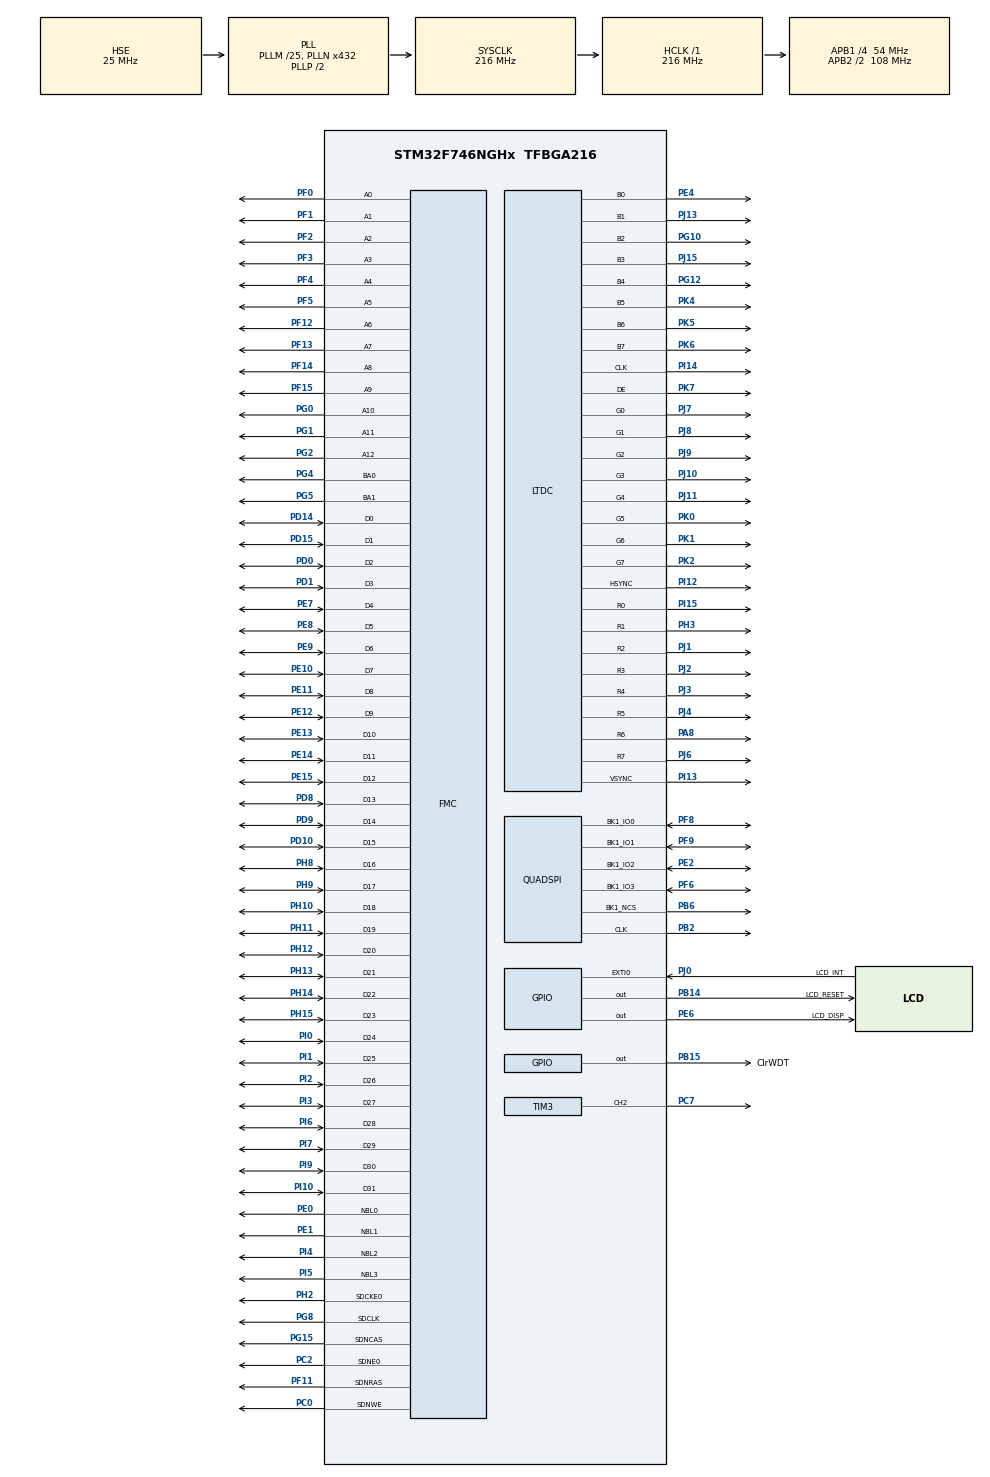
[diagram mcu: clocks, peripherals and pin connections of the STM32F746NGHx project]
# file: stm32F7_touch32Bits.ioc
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CORTEX_M7.CPU_DCache=Disabled
CORTEX_M7.CPU_ICache=Disabled
DMA2D.ColorMode=DMA2D_OUTPUT_ARGB8888
FMC.CASLatency1=FMC_SDRAM_CAS_LATENCY_3
FMC.ColumnBitsNumber1=FMC_SDRAM_COLUMN_BITS_NUM_9
FMC.ExitSelfRefreshDelay1=8
FMC.LoadToActiveDelay1=2
FMC.RCDDelay1=2
FMC.RPDelay1=2
FMC.ReadBurst1=FMC_SDRAM_RBURST_DISABLE
FMC.ReadPipeDelay1=FMC_SDRAM_RPIPE_DELAY_1
FMC.ReadPipeDelay2=FMC_SDRAM_RPIPE_DELAY_1
FMC.RowCycleDelay1=7
FMC.SDClockPeriod1=FMC_SDRAM_CLOCK_PERIOD_2
FMC.SDClockPeriod2=FMC_SDRAM_CLOCK_PERIOD_2
FMC.SelfRefreshTime1=5
FMC.WriteRecoveryTime1=3
FREERTOS.Tasks01=defaultTask,0,128,StartDefaultTask,Default,NULL,Dynamic,NULL,NULL;myTask02,-3,8192,StartTask02,Default,NULL,Dynamic,NULL,NULL;myTask03,-3,128,StartTask03,Default,NULL,Dynamic,NULL,NULL
FREERTOS.configENABLE_FPU=1
FREERTOS.configTOTAL_HEAP_SIZE=52768
FREERTOS.configUSE_NEWLIB_REENTRANT=1
LTDC.ActiveW=800
LTDC.Alpha0_L0=0
LTDC.Alpha_L0=255
LTDC.DEPolarity=LTDC_DEPOLARITY_AL
LTDC.FBStartAdress_L0=0xC0000000
LTDC.HBP=45
LTDC.HFP=210
LTDC.HSPolarity=LTDC_HSPOLARITY_AL
LTDC.HSync=2
LTDC.ImageHeight_L0=480
LTDC.ImageWidth_L0=800
LTDC.Layers=0
LTDC.PCPolarity=LTDC_PCPOLARITY_IPC
LTDC.PixelFormat_L0=LTDC_PIXEL_FORMAT_ARGB8888
LTDC.VBP=22
LTDC.VFP=22
LTDC.VSPolarity=LTDC_VSPOLARITY_AL
LTDC.VSync=2
LTDC.WindowX1_L0=800
LTDC.WindowY1_L0=480
Mcu.Family=STM32F7
Mcu.Name=STM32F746NGHx
Mcu.Package=TFBGA216
NVIC.DMA2D_IRQn=true\:5\:0\:false\:false\:true\:true\:true\:true\:true
NVIC.EXTI0_IRQn=true\:5\:0\:false\:false\:true\:true\:true\:true\:true
NVIC.LTDC_ER_IRQn=true\:5\:0\:false\:false\:true\:true\:true\:true\:true
NVIC.LTDC_IRQn=true\:5\:0\:false\:false\:true\:true\:true\:true\:true
NVIC.PriorityGroup=NVIC_PRIORITYGROUP_4
NVIC.TIM2_IRQn=true\:5\:0\:false\:false\:true\:true\:true\:true\:true
NVIC.TIM6_DAC_IRQn=true\:15\:0\:false\:false\:true\:false\:false\:true\:true
NVIC.TimeBase=TIM6_DAC_IRQn
NVIC.TimeBaseIP=TIM6
PA13.Mode=Serial_Wire
PA13.Signal=SYS_JTMS-SWDIO
PA14.Mode=Serial_Wire
PA14.Signal=SYS_JTCK-SWCLK
PA8.GPIO_Speed=GPIO_SPEED_FREQ_VERY_HIGH
PA8.Mode=RGB888
PA8.Signal=LTDC_R6
PB14.GPIO_Label=LCD_RESET
PB14.Signal=GPIO_Output
PB15.GPIO_Label=ClrWDT
PB15.Signal=GPIO_Output
PB2.Mode=Single Bank 1
PB2.Signal=QUADSPI_CLK
PB6.Mode=Single Bank 1
PB6.Signal=QUADSPI_BK1_NCS
PC0.Signal=FMC_SDNWE
PC14/OSC32_IN.Mode=LSE-External-Clock-Source
PC14/OSC32_IN.Signal=RCC_OSC32_IN
PC15/OSC32_OUT.Mode=LSE-External-Clock-Source
PC15/OSC32_OUT.Signal=RCC_OSC32_OUT
PC2.Mode=SdramChipSelect1_1
PC2.Signal=FMC_SDNE0
PC7.Signal=S_TIM3_CH2
PD0.Signal=FMC_D2_DA2
PD1.Signal=FMC_D3_DA3
PD10.Signal=FMC_D15_DA15
PD14.Signal=FMC_D0_DA0
PD15.Signal=FMC_D1_DA1
PD8.Signal=FMC_D13_DA13
PD9.Signal=FMC_D14_DA14
PE0.Signal=FMC_NBL0
PE1.Signal=FMC_NBL1
PE10.Signal=FMC_D7_DA7
PE11.Signal=FMC_D8_DA8
PE12.Signal=FMC_D9_DA9
PE13.Signal=FMC_D10_DA10
PE14.Signal=FMC_D11_DA11
PE15.Signal=FMC_D12_DA12
PE2.Mode=Single Bank 1
PE2.Signal=QUADSPI_BK1_IO2
PE4.GPIO_Speed=GPIO_SPEED_FREQ_VERY_HIGH
PE4.Mode=RGB888
PE4.Signal=LTDC_B0
PE6.GPIO_Label=LCD_DISP
PE6.Signal=GPIO_Output
PE7.Signal=FMC_D4_DA4
PE8.Signal=FMC_D5_DA5
PE9.Signal=FMC_D6_DA6
PF0.Signal=FMC_A0
PF1.Signal=FMC_A1
PF11.Signal=FMC_SDNRAS
PF12.Signal=FMC_A6
PF13.Signal=FMC_A7
PF14.Signal=FMC_A8
PF15.Signal=FMC_A9
PF2.Signal=FMC_A2
PF3.Signal=FMC_A3
PF4.Signal=FMC_A4
PF5.Signal=FMC_A5
PF6.Mode=Single Bank 1
PF6.Signal=QUADSPI_BK1_IO3
PF8.Mode=Single Bank 1
PF8.Signal=QUADSPI_BK1_IO0
PF9.Mode=Single Bank 1
PF9.Signal=QUADSPI_BK1_IO1
PG0.Signal=FMC_A10
PG1.Signal=FMC_A11
PG10.GPIO_Speed=GPIO_SPEED_FREQ_VERY_HIGH
PG10.Mode=RGB888
PG10.Signal=LTDC_B2
PG12.GPIO_Speed=GPIO_SPEED_FREQ_VERY_HIGH
PG12.Mode=RGB888
PG12.Signal=LTDC_B4
PG15.Signal=FMC_SDNCAS
PG2.Signal=FMC_A12
PG4.Signal=FMC_A14_BA0
PG5.Signal=FMC_A15_BA1
PG8.Signal=FMC_SDCLK
PH0/OSC_IN.Mode=HSE-External-Oscillator
PH0/OSC_IN.Signal=RCC_OSC_IN
PH1/OSC_OUT.Mode=HSE-External-Oscillator
PH1/OSC_OUT.Signal=RCC_OSC_OUT
PH10.Signal=FMC_D18
PH11.Signal=FMC_D19
PH12.Signal=FMC_D20
PH13.Signal=FMC_D21
PH14.Signal=FMC_D22
PH15.Signal=FMC_D23
PH2.Mode=SdramChipSelect1_1
PH2.Signal=FMC_SDCKE0
PH3.GPIO_Speed=GPIO_SPEED_FREQ_VERY_HIGH
PH3.Mode=RGB888
PH3.Signal=LTDC_R1
PH4.GPIO_Pu=GPIO_PULLUP
PH4.Signal=I2C2_SCL
PH5.GPIO_Pu=GPIO_PULLUP
PH5.Signal=I2C2_SDA
PH8.Signal=FMC_D16
PH9.Signal=FMC_D17
PI0.Signal=FMC_D24
PI1.Signal=FMC_D25
PI10.Signal=FMC_D31
PI12.GPIO_Speed=GPIO_SPEED_FREQ_VERY_HIGH
PI12.Mode=RGB888
PI12.Signal=LTDC_HSYNC
PI13.GPIO_Speed=GPIO_SPEED_FREQ_VERY_HIGH
PI13.Mode=RGB888
PI13.Signal=LTDC_VSYNC
PI14.GPIO_Speed=GPIO_SPEED_FREQ_VERY_HIGH
PI14.Mode=RGB888
PI14.Signal=LTDC_CLK
PI15.GPIO_Speed=GPIO_SPEED_FREQ_VERY_HIGH
PI15.Mode=RGB888
PI15.Signal=LTDC_R0
PI2.Signal=FMC_D26
PI3.Signal=FMC_D27
PI4.Signal=FMC_NBL2
PI5.Signal=FMC_NBL3
PI6.Signal=FMC_D28
PI7.Signal=FMC_D29
PI9.Signal=FMC_D30
PJ0.GPIO_Label=LCD_INT
PJ0.GPIO_ModeDefaultEXTI=GPIO_MODE_IT_FALLING
PJ0.Signal=GPXTI0
PJ1.GPIO_Speed=GPIO_SPEED_FREQ_VERY_HIGH
PJ1.Mode=RGB888
PJ1.Signal=LTDC_R2
PJ10.GPIO_Speed=GPIO_SPEED_FREQ_VERY_HIGH
PJ10.Mode=RGB888
PJ10.Signal=LTDC_G3
PJ11.GPIO_Speed=GPIO_SPEED_FREQ_VERY_HIGH
PJ11.Mode=RGB888
PJ11.Signal=LTDC_G4
PJ13.GPIO_Speed=GPIO_SPEED_FREQ_VERY_HIGH
PJ13.Mode=RGB888
PJ13.Signal=LTDC_B1
PJ15.GPIO_Speed=GPIO_SPEED_FREQ_VERY_HIGH
PJ15.Mode=RGB888
PJ15.Signal=LTDC_B3
PJ2.GPIO_Speed=GPIO_SPEED_FREQ_VERY_HIGH
PJ2.Mode=RGB888
PJ2.Signal=LTDC_R3
PJ3.GPIO_Speed=GPIO_SPEED_FREQ_VERY_HIGH
PJ3.Mode=RGB888
PJ3.Signal=LTDC_R4
PJ4.GPIO_Speed=GPIO_SPEED_FREQ_VERY_HIGH
PJ4.Mode=RGB888
PJ4.Signal=LTDC_R5
PJ6.GPIO_Speed=GPIO_SPEED_FREQ_VERY_HIGH
PJ6.Mode=RGB888
PJ6.Signal=LTDC_R7
PJ7.GPIO_Speed=GPIO_SPEED_FREQ_VERY_HIGH
PJ7.Mode=RGB888
PJ7.Signal=LTDC_G0
PJ8.GPIO_Speed=GPIO_SPEED_FREQ_VERY_HIGH
PJ8.Mode=RGB888
PJ8.Signal=LTDC_G1
PJ9.GPIO_Speed=GPIO_SPEED_FREQ_VERY_HIGH
PJ9.Mode=RGB888
PJ9.Signal=LTDC_G2
PK0.GPIO_Speed=GPIO_SPEED_FREQ_VERY_HIGH
PK0.Mode=RGB888
PK0.Signal=LTDC_G5
PK1.GPIO_Speed=GPIO_SPEED_FREQ_VERY_HIGH
PK1.Mode=RGB888
PK1.Signal=LTDC_G6
PK2.GPIO_Speed=GPIO_SPEED_FREQ_VERY_HIGH
PK2.Mode=RGB888
PK2.Signal=LTDC_G7
PK4.GPIO_Speed=GPIO_SPEED_FREQ_VERY_HIGH
PK4.Mode=RGB888
PK4.Signal=LTDC_B5
PK5.GPIO_Speed=GPIO_SPEED_FREQ_VERY_HIGH
PK5.Mode=RGB888
PK5.Signal=LTDC_B6
PK6.GPIO_Speed=GPIO_SPEED_FREQ_VERY_HIGH
PK6.Mode=RGB888
PK6.Signal=LTDC_B7
PK7.GPIO_Speed=GPIO_SPEED_FREQ_VERY_HIGH
PK7.Mode=RGB888
PK7.Signal=LTDC_DE
ProjectManager.HeapSize=0x200
ProjectManager.StackSize=0x400
ProjectManager.TargetToolchain=STM32CubeIDE
QUADSPI.ChipSelectHighTime=QSPI_CS_HIGH_TIME_2_CYCLE
QUADSPI.ClockPrescaler=2
QUADSPI.FifoThreshold=4
QUADSPI.FlashSize=31
QUADSPI.SampleShifting=QSPI_SAMPLE_SHIFTING_HALFCYCLE
RCC.AHBFreq_Value=216000000
RCC.APB1CLKDivider=RCC_HCLK_DIV4
RCC.APB1Freq_Value=54000000
RCC.APB1TimFreq_Value=108000000
RCC.APB2CLKDivider=RCC_HCLK_DIV2
RCC.APB2Freq_Value=108000000
RCC.APB2TimFreq_Value=216000000
RCC.CortexFreq_Value=216000000
RCC.HCLKFreq_Value=216000000
RCC.HSE_VALUE=25000000
RCC.HSI_VALUE=16000000
RCC.LSE_VALUE=32768
RCC.PLLM=25
RCC.PLLN=432
RCC.PLLSAIR=3
RCC.PLLSourceVirtual=RCC_PLLSOURCE_HSE
RCC.SYSCLKFreq_VALUE=216000000
RCC.SYSCLKSource=RCC_SYSCLKSOURCE_PLLCLK
RCC.USBFreq_Value=216000000
RCC.VCOOutputFreq_Value=432000000
SH.FMC_A0.0=FMC_A0,13b-sda1
SH.FMC_A1.0=FMC_A1,13b-sda1
SH.FMC_A10.0=FMC_A10,13b-sda1
SH.FMC_A11.0=FMC_A11,13b-sda1
SH.FMC_A12.0=FMC_A12,13b-sda1
SH.FMC_A14_BA0.0=FMC_BA0,FourSdramBanks1
SH.FMC_A15_BA1.0=FMC_BA1,FourSdramBanks1
SH.FMC_A2.0=FMC_A2,13b-sda1
SH.FMC_A3.0=FMC_A3,13b-sda1
SH.FMC_A4.0=FMC_A4,13b-sda1
SH.FMC_A5.0=FMC_A5,13b-sda1
SH.FMC_A6.0=FMC_A6,13b-sda1
SH.FMC_A7.0=FMC_A7,13b-sda1
SH.FMC_A8.0=FMC_A8,13b-sda1
SH.FMC_A9.0=FMC_A9,13b-sda1
SH.FMC_D0_DA0.0=FMC_D0,sd-32b-d1
SH.FMC_D10_DA10.0=FMC_D10,sd-32b-d1
SH.FMC_D11_DA11.0=FMC_D11,sd-32b-d1
SH.FMC_D12_DA12.0=FMC_D12,sd-32b-d1
SH.FMC_D13_DA13.0=FMC_D13,sd-32b-d1
SH.FMC_D14_DA14.0=FMC_D14,sd-32b-d1
SH.FMC_D15_DA15.0=FMC_D15,sd-32b-d1
SH.FMC_D16.0=FMC_D16,sd-32b-d1
SH.FMC_D17.0=FMC_D17,sd-32b-d1
SH.FMC_D18.0=FMC_D18,sd-32b-d1
SH.FMC_D19.0=FMC_D19,sd-32b-d1
SH.FMC_D1_DA1.0=FMC_D1,sd-32b-d1
SH.FMC_D20.0=FMC_D20,sd-32b-d1
SH.FMC_D21.0=FMC_D21,sd-32b-d1
SH.FMC_D22.0=FMC_D22,sd-32b-d1
SH.FMC_D23.0=FMC_D23,sd-32b-d1
SH.FMC_D24.0=FMC_D24,sd-32b-d1
SH.FMC_D25.0=FMC_D25,sd-32b-d1
SH.FMC_D26.0=FMC_D26,sd-32b-d1
SH.FMC_D27.0=FMC_D27,sd-32b-d1
SH.FMC_D28.0=FMC_D28,sd-32b-d1
SH.FMC_D29.0=FMC_D29,sd-32b-d1
SH.FMC_D2_DA2.0=FMC_D2,sd-32b-d1
SH.FMC_D30.0=FMC_D30,sd-32b-d1
SH.FMC_D31.0=FMC_D31,sd-32b-d1
SH.FMC_D3_DA3.0=FMC_D3,sd-32b-d1
SH.FMC_D4_DA4.0=FMC_D4,sd-32b-d1
SH.FMC_D5_DA5.0=FMC_D5,sd-32b-d1
SH.FMC_D6_DA6.0=FMC_D6,sd-32b-d1
SH.FMC_D7_DA7.0=FMC_D7,sd-32b-d1
SH.FMC_D8_DA8.0=FMC_D8,sd-32b-d1
SH.FMC_D9_DA9.0=FMC_D9,sd-32b-d1
SH.FMC_NBL0.0=FMC_NBL0,Sd4ByteEnable1
SH.FMC_NBL1.0=FMC_NBL1,Sd4ByteEnable1
SH.FMC_NBL2.0=FMC_NBL2,Sd4ByteEnable1
SH.FMC_NBL3.0=FMC_NBL3,Sd4ByteEnable1
SH.FMC_SDCLK.0=FMC_SDCLK,13b-sda1
SH.FMC_SDNCAS.0=FMC_SDNCAS,13b-sda1
SH.FMC_SDNRAS.0=FMC_SDNRAS,13b-sda1
SH.FMC_SDNWE.0=FMC_SDNWE,13b-sda1
SH.S_TIM3_CH2.0=TIM3_CH2,PWM Generation2 CH2
STMicroelectronics.X-CUBE-TOUCHGFX.4.24.1.ApplicationCcGraphicsJjApplication=TouchGFXOoGenerator
STMicroelectronics.X-CUBE-TOUCHGFX.4.24.1.tgfx_address1=0xC0000000
STMicroelectronics.X-CUBE-TOUCHGFX.4.24.1.tgfx_display_interface=disp_ltdc
STMicroelectronics.X-CUBE-TOUCHGFX.4.24.1.tgfx_hardware_accelerator=dma_2d
STMicroelectronics.X-CUBE-TOUCHGFX.4.24.1.tgfx_location=By Address
STMicroelectronics.X-CUBE-TOUCHGFX.4.24.1.tgfx_vsync=vsync_ltdc
STMicroelectronics.X-CUBE-TOUCHGFX.4.24.1_IsPackSelfContextualization=true
TIM2.Period=100
TIM2.Prescaler=54
TIM3.Channel-PWM\ Generation2\ CH2=TIM_CHANNEL_2
TIM3.Period=100
TIM3.Prescaler=108
TIM3.Pulse-PWM\ Generation2\ CH2=50
VP_CRC_VS_CRC.Mode=CRC_Activate
VP_DMA2D_VS_DMA2D.Mode=DMA2D_Activate
VP_FREERTOS_VS_CMSIS_V1.Mode=CMSIS_V1
VP_STMicroelectronics.X-CUBE-TOUCHGFX_VS_GraphicsJjApplication_4.24.1.Mode=GraphicsJjApplication
VP_SYS_VS_tim6.Mode=TIM6
VP_TIM2_VS_ClockSourceINT.Mode=Internal
VP_TIM3_VS_ClockSourceINT.Mode=Internal
board=custom

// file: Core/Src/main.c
/* USER CODE BEGIN Header */
/**
  ******************************************************************************
  * @file           : main.c
  * @brief          : Main program body
  ******************************************************************************
  * @attention
  *
  * Copyright (c) 2025 STMicroelectronics.
  * All rights reserved.
  *
  * This software is licensed under terms that can be found in the LICENSE file
  * in the root directory of this software component.
  * If no LICENSE file comes with this software, it is provided AS-IS.
  *
  ******************************************************************************
  */
/* USER CODE END Header */
#include "main.h"
#include "cmsis_os.h"
#include "app_touchgfx.h"

/* USER CODE BEGIN Includes */
#include "GT911.h"
/* USER CODE END Includes */

/* USER CODE BEGIN PD */
#define SDRAM_START_ADDR ((uint32_t)0xC0000000)
#define SDRAM_SIZE       ((uint32_t)0x200000) // 2MB for testing
#define SDRAM_TEST_DATA  ((uint32_t)0x12345678)

#define SDRAM_START_ADDRESS 0xC0000000

#define SDRAM_TIMEOUT     ((uint32_t)0xFFFF)

#define SDRAM_MODEREG_BURST_LENGTH_1             ((uint16_t)0x0000)
#define SDRAM_MODEREG_BURST_LENGTH_2             ((uint16_t)0x0001)
#define SDRAM_MODEREG_BURST_LENGTH_4             ((uint16_t)0x0002)
#define SDRAM_MODEREG_BURST_LENGTH_8             ((uint16_t)0x0004)
#define SDRAM_MODEREG_BURST_TYPE_SEQUENTIAL      ((uint16_t)0x0000)
#define SDRAM_MODEREG_BURST_TYPE_INTERLEAVED     ((uint16_t)0x0008)
#define SDRAM_MODEREG_CAS_LATENCY_2              ((uint16_t)0x0020)
#define SDRAM_MODEREG_CAS_LATENCY_3              ((uint16_t)0x0030)
#define SDRAM_MODEREG_OPERATING_MODE_STANDARD    ((uint16_t)0x0000)
#define SDRAM_MODEREG_WRITEBURST_MODE_PROGRAMMED ((uint16_t)0x0000)
#define SDRAM_MODEREG_WRITEBURST_MODE_SINGLE     ((uint16_t)0x0200)
/* USER CODE END PD */

CRC_HandleTypeDef hcrc;

DMA2D_HandleTypeDef hdma2d;

LTDC_HandleTypeDef hltdc;

QSPI_HandleTypeDef hqspi;

TIM_HandleTypeDef htim2;
TIM_HandleTypeDef htim3;

SDRAM_HandleTypeDef hsdram1;

osThreadId defaultTaskHandle;
osThreadId myTask02Handle;
osThreadId myTask03Handle;

void SystemClock_Config(void);
static void MX_GPIO_Init(void);
static void MX_FMC_Init(void);
static void MX_LTDC_Init(void);
static void MX_DMA2D_Init(void);
static void MX_TIM3_Init(void);
static void MX_CRC_Init(void);
static void MX_QUADSPI_Init(void);
static void MX_TIM2_Init(void);
void StartDefaultTask(void const * argument);
void StartTask02(void const * argument);
void StartTask03(void const * argument);

/* USER CODE BEGIN 0 */
//void MX_QUADSPI_Init(void)
//{
//    /* QSPI init function */
//    hqspi.Instance = QUADSPI;
//    hqspi.Init.ClockPrescaler = 2; // 216MHz / (2+1) = 72MHz QSPI Clock
//    hqspi.Init.FifoThreshold = 4;
//    hqspi.Init.SampleShifting = QSPI_SAMPLE_SHIFTING_HALFCYCLE;
//    hqspi.Init.FlashSize = 31; // 2^31 = 2GB address space (we need for 256Mbit = 32MB)
//    hqspi.Init.ChipSelectHighTime = QSPI_CS_HIGH_TIME_2_CYCLE;
//    hqspi.Init.ClockMode = QSPI_CLOCK_MODE_0;
//    hqspi.Init.FlashID = QSPI_FLASH_ID_1; // Bank 1
//    hqspi.Init.DualFlash = QSPI_DUALFLASH_DISABLE;
//
//    if (HAL_QSPI_Init(&hqspi) != HAL_OK)
//    {
//        Error_Handler();
//    }
//
//    /* Enter 4-byte addressing mode for W25Q256 */
//    QSPI_CommandTypeDef sCommand = {0};
//
//    sCommand.InstructionMode = QSPI_INSTRUCTION_1_LINE;
//    sCommand.Instruction = 0xB7; // Enter 4-byte address mode
//    sCommand.AddressMode = QSPI_ADDRESS_NONE;
//    sCommand.AlternateByteMode = QSPI_ALTERNATE_BYTES_NONE;
//    sCommand.DataMode = QSPI_DATA_NONE;
//    sCommand.DummyCycles = 0;
//
//    if (HAL_QSPI_Command(&hqspi, &sCommand, HAL_QPSI_TIMEOUT_DEFAULT_VALUE) != HAL_OK)
//    {
//        Error_Handler();
//    }
//}

void QSPI_EnableMemoryMappedMode(void)
{
    QSPI_CommandTypeDef sCommand = {0};
    QSPI_MemoryMappedTypeDef sMemMappedCfg = {0};

    /* Configure QSPI command for read */
    sCommand.InstructionMode = QSPI_INSTRUCTION_1_LINE;
    sCommand.Instruction = 0xEB; // Quad I/O Fast Read
    sCommand.AddressMode = QSPI_ADDRESS_4_LINES;
    sCommand.AddressSize = QSPI_ADDRESS_32_BITS;
    sCommand.AlternateByteMode = QSPI_ALTERNATE_BYTES_4_LINES;
    sCommand.AlternateBytesSize = QSPI_ALTERNATE_BYTES_8_BITS;
    sCommand.AlternateBytes = 0x00; // Typically 0x00 for Winbond
    sCommand.DataMode = QSPI_DATA_4_LINES;
    sCommand.DummyCycles = 6; // 6 dummy cycles is typical (datasheet recommends 6 for 72MHz)
    sCommand.DdrMode = QSPI_DDR_MODE_DISABLE;
    sCommand.DdrHoldHalfCycle = QSPI_DDR_HHC_ANALOG_DELAY;
    sCommand.SIOOMode = QSPI_SIOO_INST_EVERY_CMD;

    /* Configure memory mapped mode */
    sMemMappedCfg.TimeOutActivation = QSPI_TIMEOUT_COUNTER_DISABLE;
    sMemMappedCfg.TimeOutPeriod = 0;

    if (HAL_QSPI_MemoryMapped(&hqspi, &sCommand, &sMemMappedCfg) != HAL_OK)
    {
        Error_Handler();
    }
}

/**
  * @brief  Perform the SDRAM external memory initialization sequence
  * @param  hsdram: SDRAM handle
  * @param  Command: Pointer to SDRAM command structure
  * @retval None
  */
static void BSP_SDRAM_Initialization_Sequence(SDRAM_HandleTypeDef *hsdram, FMC_SDRAM_CommandTypeDef *Command)
{
  __IO uint32_t tmpmrd =0;
  /* Step 3:  Configure a clock configuration enable command */
  Command->CommandMode = FMC_SDRAM_CMD_CLK_ENABLE;
  Command->CommandTarget = FMC_SDRAM_CMD_TARGET_BANK1;
  Command->AutoRefreshNumber = 1;
  Command->ModeRegisterDefinition = 0;

  /* Send the command */
  HAL_SDRAM_SendCommand(hsdram, Command, SDRAM_TIMEOUT);

  /* Step 4: Insert 100 us minimum delay */
  /* Inserted delay is equal to 1 ms due to systick time base unit (ms) */
  HAL_Delay(1);

  /* Step 5: Configure a PALL (precharge all) command */
  Command->CommandMode = FMC_SDRAM_CMD_PALL;
  Command->CommandTarget = FMC_SDRAM_CMD_TARGET_BANK1;
  Command->AutoRefreshNumber = 1;
  Command->ModeRegisterDefinition = 0;

  /* Send the command */
  HAL_SDRAM_SendCommand(hsdram, Command, SDRAM_TIMEOUT);

  /* Step 6 : Configure a Auto-Refresh command */
  Command->CommandMode = FMC_SDRAM_CMD_AUTOREFRESH_MODE;
  Command->CommandTarget = FMC_SDRAM_CMD_TARGET_BANK1;
  Command->AutoRefreshNumber = 8;
  Command->ModeRegisterDefinition = 0;

  /* Send the command */
  HAL_SDRAM_SendCommand(hsdram, Command, SDRAM_TIMEOUT);

  /* Step 7: Program the external memory mode register */
  tmpmrd = (uint32_t)SDRAM_MODEREG_BURST_LENGTH_1          |
                     SDRAM_MODEREG_BURST_TYPE_SEQUENTIAL   |
                     SDRAM_MODEREG_CAS_LATENCY_2           |
                     SDRAM_MODEREG_OPERATING_MODE_STANDARD |
                     SDRAM_MODEREG_WRITEBURST_MODE_SINGLE;

  Command->CommandMode = FMC_SDRAM_CMD_LOAD_MODE;
  Command->CommandTarget = FMC_SDRAM_CMD_TARGET_BANK1;
  Command->AutoRefreshNumber = 1;
  Command->ModeRegisterDefinition = tmpmrd;

  /* Send the command */
  HAL_SDRAM_SendCommand(hsdram, Command, SDRAM_TIMEOUT);

  /* Step 8: Set the refresh rate counter */
  /* (15.62 us x Freq) - 20 */
  /* Set the device refresh counter */
  hsdram->Instance->SDRTR |= ((uint32_t)((1292)<< 1));

}

uint8_t wdata[] = {0, 0, 0, 0, 0};
uint8_t rdata[10];

void MPU_Config(void)
{
    MPU_Region_InitTypeDef MPU_InitStruct = {0};

    HAL_MPU_Disable();

    // Configure MPU region for 32MB QSPI at 0x90000000
    MPU_InitStruct.Enable           = MPU_REGION_ENABLE;
    MPU_InitStruct.BaseAddress      = 0x90000000;
    MPU_InitStruct.Size             = MPU_REGION_SIZE_32MB;
    MPU_InitStruct.AccessPermission = MPU_REGION_FULL_ACCESS;
    MPU_InitStruct.IsBufferable     = MPU_ACCESS_NOT_BUFFERABLE;
    MPU_InitStruct.IsCacheable      = MPU_ACCESS_CACHEABLE;
    MPU_InitStruct.IsShareable      = MPU_ACCESS_NOT_SHAREABLE;
    MPU_InitStruct.Number           = MPU_REGION_NUMBER0;
    MPU_InitStruct.TypeExtField     = MPU_TEX_LEVEL1;
    MPU_InitStruct.SubRegionDisable = 0x00;
    MPU_InitStruct.DisableExec      = MPU_INSTRUCTION_ACCESS_DISABLE;

    HAL_MPU_ConfigRegion(&MPU_InitStruct);
    HAL_MPU_Enable(MPU_PRIVILEGED_DEFAULT);
}

/* USER CODE END 0 */

int main(void)
{

  /* USER CODE BEGIN 1 */
//	MPU_Config();
  /* USER CODE END 1 */

  /* MCU Configuration--------------------------------------------------------*/

  /* Reset of all peripherals, Initializes the Flash interface and the Systick. */
  HAL_Init();

  /* Configure the system clock */
  SystemClock_Config();

  /* Initialize all configured peripherals */
  MX_GPIO_Init();
  MX_FMC_Init();
  MX_LTDC_Init();
  MX_DMA2D_Init();
  MX_TIM3_Init();
  MX_CRC_Init();
  MX_QUADSPI_Init();
  MX_TIM2_Init();
  MX_TouchGFX_Init();
  /* Call PreOsInit function */
  MX_TouchGFX_PreOSInit();
  /* USER CODE BEGIN 2 */

  HAL_GPIO_WritePin(LCD_DISP_GPIO_Port, LCD_DISP_Pin, GPIO_PIN_SET);

  htim3.Instance->CCR2 = 1;
  HAL_TIM_PWM_Start(&htim3, TIM_CHANNEL_2);   // Start PWM on channel 2
  HAL_TIM_Base_Start_IT(&htim2);

  //memcpy(0, ram_buffer, image_size);
//  for(uint32_t i =0 ;i<2000;i+=5)
//  {
//	  memcpy((uint32_t *) SDRAM_START_ADDR+i, wdata,5);
//  }
  /* USER CODE END 2 */

  /* Create the thread(s) */
  /* definition and creation of defaultTask */
  osThreadDef(defaultTask, StartDefaultTask, osPriorityNormal, 0, 128);
  defaultTaskHandle = osThreadCreate(osThread(defaultTask), NULL);

  /* definition and creation of myTask02 */
  osThreadDef(myTask02, StartTask02, osPriorityIdle, 0, 8192);
  myTask02Handle = osThreadCreate(osThread(myTask02), NULL);

  /* definition and creation of myTask03 */
  osThreadDef(myTask03, StartTask03, osPriorityIdle, 0, 128);
  myTask03Handle = osThreadCreate(osThread(myTask03), NULL);

  /* Start scheduler */
  osKernelStart();

  /* We should never get here as control is now taken by the scheduler */

  /* Infinite loop */
  while (1)
  {

  }
}

void SystemClock_Config(void)
{
  RCC_OscInitTypeDef RCC_OscInitStruct = {0};
  RCC_ClkInitTypeDef RCC_ClkInitStruct = {0};

  /** Configure the main internal regulator output voltage
  */
  __HAL_RCC_PWR_CLK_ENABLE();
  __HAL_PWR_VOLTAGESCALING_CONFIG(PWR_REGULATOR_VOLTAGE_SCALE1);

  /** Initializes the RCC Oscillators according to the specified parameters
  * in the RCC_OscInitTypeDef structure.
  */
  RCC_OscInitStruct.OscillatorType = RCC_OSCILLATORTYPE_HSE;
  RCC_OscInitStruct.HSEState = RCC_HSE_ON;
  RCC_OscInitStruct.PLL.PLLState = RCC_PLL_ON;
  RCC_OscInitStruct.PLL.PLLSource = RCC_PLLSOURCE_HSE;
  RCC_OscInitStruct.PLL.PLLM = 25;
  RCC_OscInitStruct.PLL.PLLN = 432;
  RCC_OscInitStruct.PLL.PLLP = RCC_PLLP_DIV2;
  RCC_OscInitStruct.PLL.PLLQ = 2;
  if (HAL_RCC_OscConfig(&RCC_OscInitStruct) != HAL_OK)
  {
    Error_Handler();
  }

  /** Activate the Over-Drive mode
  */
  if (HAL_PWREx_EnableOverDrive() != HAL_OK)
  {
    Error_Handler();
  }

  /** Initializes the CPU, AHB and APB buses clocks
  */
  RCC_ClkInitStruct.ClockType = RCC_CLOCKTYPE_HCLK|RCC_CLOCKTYPE_SYSCLK
                              |RCC_CLOCKTYPE_PCLK1|RCC_CLOCKTYPE_PCLK2;
  RCC_ClkInitStruct.SYSCLKSource = RCC_SYSCLKSOURCE_PLLCLK;
  RCC_ClkInitStruct.AHBCLKDivider = RCC_SYSCLK_DIV1;
  RCC_ClkInitStruct.APB1CLKDivider = RCC_HCLK_DIV4;
  RCC_ClkInitStruct.APB2CLKDivider = RCC_HCLK_DIV2;

  if (HAL_RCC_ClockConfig(&RCC_ClkInitStruct, FLASH_LATENCY_7) != HAL_OK)
  {
    Error_Handler();
  }
}

static void MX_CRC_Init(void)
{

  hcrc.Instance = CRC;
  hcrc.Init.DefaultPolynomialUse = DEFAULT_POLYNOMIAL_ENABLE;
  hcrc.Init.DefaultInitValueUse = DEFAULT_INIT_VALUE_ENABLE;
  hcrc.Init.InputDataInversionMode = CRC_INPUTDATA_INVERSION_NONE;
  hcrc.Init.OutputDataInversionMode = CRC_OUTPUTDATA_INVERSION_DISABLE;
  hcrc.InputDataFormat = CRC_INPUTDATA_FORMAT_BYTES;
  if (HAL_CRC_Init(&hcrc) != HAL_OK)
  {
    Error_Handler();
  }

}

static void MX_DMA2D_Init(void)
{

  hdma2d.Instance = DMA2D;
  hdma2d.Init.Mode = DMA2D_M2M;
  hdma2d.Init.ColorMode = DMA2D_OUTPUT_ARGB8888;
  hdma2d.Init.OutputOffset = 0;
  hdma2d.LayerCfg[1].InputOffset = 0;
  hdma2d.LayerCfg[1].InputColorMode = DMA2D_INPUT_ARGB8888;
  hdma2d.LayerCfg[1].AlphaMode = DMA2D_NO_MODIF_ALPHA;
  hdma2d.LayerCfg[1].InputAlpha = 0;
  if (HAL_DMA2D_Init(&hdma2d) != HAL_OK)
  {
    Error_Handler();
  }
  if (HAL_DMA2D_ConfigLayer(&hdma2d, 1) != HAL_OK)
  {
    Error_Handler();
  }

}

static void MX_LTDC_Init(void)
{

  LTDC_LayerCfgTypeDef pLayerCfg = {0};

  hltdc.Instance = LTDC;
  hltdc.Init.HSPolarity = LTDC_HSPOLARITY_AL;
  hltdc.Init.VSPolarity = LTDC_VSPOLARITY_AL;
  hltdc.Init.DEPolarity = LTDC_DEPOLARITY_AL;
  hltdc.Init.PCPolarity = LTDC_PCPOLARITY_IPC;
  hltdc.Init.HorizontalSync = 1;
  hltdc.Init.VerticalSync = 1;
  hltdc.Init.AccumulatedHBP = 46;
  hltdc.Init.AccumulatedVBP = 23;
  hltdc.Init.AccumulatedActiveW = 846;
  hltdc.Init.AccumulatedActiveH = 503;
  hltdc.Init.TotalWidth = 1056;
  hltdc.Init.TotalHeigh = 525;
  hltdc.Init.Backcolor.Blue = 0;
  hltdc.Init.Backcolor.Green = 0;
  hltdc.Init.Backcolor.Red = 0;
  if (HAL_LTDC_Init(&hltdc) != HAL_OK)
  {
    Error_Handler();
  }
  pLayerCfg.WindowX0 = 0;
  pLayerCfg.WindowX1 = 800;
  pLayerCfg.WindowY0 = 0;
  pLayerCfg.WindowY1 = 480;
  pLayerCfg.PixelFormat = LTDC_PIXEL_FORMAT_ARGB8888;
  pLayerCfg.Alpha = 255;
  pLayerCfg.Alpha0 = 0;
  pLayerCfg.BlendingFactor1 = LTDC_BLENDING_FACTOR1_CA;
  pLayerCfg.BlendingFactor2 = LTDC_BLENDING_FACTOR2_CA;
  pLayerCfg.FBStartAdress = 0xC0000000;
  pLayerCfg.ImageWidth = 800;
  pLayerCfg.ImageHeight = 480;
  pLayerCfg.Backcolor.Blue = 0;
  pLayerCfg.Backcolor.Green = 0;
  pLayerCfg.Backcolor.Red = 0;
  if (HAL_LTDC_ConfigLayer(&hltdc, &pLayerCfg, 0) != HAL_OK)
  {
    Error_Handler();
  }

}

static void MX_QUADSPI_Init(void)
{

  /* QUADSPI parameter configuration*/
  hqspi.Instance = QUADSPI;
  hqspi.Init.ClockPrescaler = 2;
  hqspi.Init.FifoThreshold = 4;
  hqspi.Init.SampleShifting = QSPI_SAMPLE_SHIFTING_HALFCYCLE;
  hqspi.Init.FlashSize = 31;
  hqspi.Init.ChipSelectHighTime = QSPI_CS_HIGH_TIME_2_CYCLE;
  hqspi.Init.ClockMode = QSPI_CLOCK_MODE_0;
  hqspi.Init.FlashID = QSPI_FLASH_ID_1;
  hqspi.Init.DualFlash = QSPI_DUALFLASH_DISABLE;
  if (HAL_QSPI_Init(&hqspi) != HAL_OK)
  {
    Error_Handler();
  }
  /* USER CODE BEGIN QUADSPI_Init 2 */
  if (CSP_QUADSPI_Init() != HAL_OK)Error_Handler();
  if (CSP_QSPI_EnableMemoryMappedMode() != HAL_OK)Error_Handler();
  /* USER CODE END QUADSPI_Init 2 */

}

static void MX_TIM2_Init(void)
{

  TIM_ClockConfigTypeDef sClockSourceConfig = {0};
  TIM_MasterConfigTypeDef sMasterConfig = {0};

  htim2.Instance = TIM2;
  htim2.Init.Prescaler = 54;
  htim2.Init.CounterMode = TIM_COUNTERMODE_UP;
  htim2.Init.Period = 100;
  htim2.Init.ClockDivision = TIM_CLOCKDIVISION_DIV1;
  htim2.Init.AutoReloadPreload = TIM_AUTORELOAD_PRELOAD_DISABLE;
  if (HAL_TIM_Base_Init(&htim2) != HAL_OK)
  {
    Error_Handler();
  }
  sClockSourceConfig.ClockSource = TIM_CLOCKSOURCE_INTERNAL;
  if (HAL_TIM_ConfigClockSource(&htim2, &sClockSourceConfig) != HAL_OK)
  {
    Error_Handler();
  }
  sMasterConfig.MasterOutputTrigger = TIM_TRGO_RESET;
  sMasterConfig.MasterSlaveMode = TIM_MASTERSLAVEMODE_DISABLE;
  if (HAL_TIMEx_MasterConfigSynchronization(&htim2, &sMasterConfig) != HAL_OK)
  {
    Error_Handler();
  }

}

static void MX_TIM3_Init(void)
{

  TIM_ClockConfigTypeDef sClockSourceConfig = {0};
  TIM_MasterConfigTypeDef sMasterConfig = {0};
  TIM_OC_InitTypeDef sConfigOC = {0};

  htim3.Instance = TIM3;
  htim3.Init.Prescaler = 108;
  htim3.Init.CounterMode = TIM_COUNTERMODE_UP;
  htim3.Init.Period = 100;
  htim3.Init.ClockDivision = TIM_CLOCKDIVISION_DIV1;
  htim3.Init.AutoReloadPreload = TIM_AUTORELOAD_PRELOAD_DISABLE;
  if (HAL_TIM_Base_Init(&htim3) != HAL_OK)
  {
    Error_Handler();
  }
  sClockSourceConfig.ClockSource = TIM_CLOCKSOURCE_INTERNAL;
  if (HAL_TIM_ConfigClockSource(&htim3, &sClockSourceConfig) != HAL_OK)
  {
    Error_Handler();
  }
  if (HAL_TIM_PWM_Init(&htim3) != HAL_OK)
  {
    Error_Handler();
  }
  sMasterConfig.MasterOutputTrigger = TIM_TRGO_RESET;
  sMasterConfig.MasterSlaveMode = TIM_MASTERSLAVEMODE_DISABLE;
  if (HAL_TIMEx_MasterConfigSynchronization(&htim3, &sMasterConfig) != HAL_OK)
  {
    Error_Handler();
  }
  sConfigOC.OCMode = TIM_OCMODE_PWM1;
  sConfigOC.Pulse = 50;
  sConfigOC.OCPolarity = TIM_OCPOLARITY_HIGH;
  sConfigOC.OCFastMode = TIM_OCFAST_DISABLE;
  if (HAL_TIM_PWM_ConfigChannel(&htim3, &sConfigOC, TIM_CHANNEL_2) != HAL_OK)
  {
    Error_Handler();
  }
  HAL_TIM_MspPostInit(&htim3);

}

/* FMC initialization function */
static void MX_FMC_Init(void)
{

  FMC_SDRAM_TimingTypeDef SdramTiming = {0};

  /** Perform the SDRAM1 memory initialization sequence
  */
  hsdram1.Instance = FMC_SDRAM_DEVICE;
  /* hsdram1.Init */
  hsdram1.Init.SDBank = FMC_SDRAM_BANK1;
  hsdram1.Init.ColumnBitsNumber = FMC_SDRAM_COLUMN_BITS_NUM_9;
  hsdram1.Init.RowBitsNumber = FMC_SDRAM_ROW_BITS_NUM_13;
  hsdram1.Init.MemoryDataWidth = FMC_SDRAM_MEM_BUS_WIDTH_32;
  hsdram1.Init.InternalBankNumber = FMC_SDRAM_INTERN_BANKS_NUM_4;
  hsdram1.Init.CASLatency = FMC_SDRAM_CAS_LATENCY_3;
  hsdram1.Init.WriteProtection = FMC_SDRAM_WRITE_PROTECTION_DISABLE;
  hsdram1.Init.SDClockPeriod = FMC_SDRAM_CLOCK_PERIOD_2;
  hsdram1.Init.ReadBurst = FMC_SDRAM_RBURST_DISABLE;
  hsdram1.Init.ReadPipeDelay = FMC_SDRAM_RPIPE_DELAY_1;
  /* SdramTiming */
  SdramTiming.LoadToActiveDelay = 2;
  SdramTiming.ExitSelfRefreshDelay = 8;
  SdramTiming.SelfRefreshTime = 5;
  SdramTiming.RowCycleDelay = 7;
  SdramTiming.WriteRecoveryTime = 3;
  SdramTiming.RPDelay = 2;
  SdramTiming.RCDDelay = 2;

  if (HAL_SDRAM_Init(&hsdram1, &SdramTiming) != HAL_OK)
  {
    Error_Handler( );
  }

  /* USER CODE BEGIN FMC_Init 2 */
  BSP_SDRAM_Initialization_Sequence(&hsdram1, &SdramTiming);
  /* USER CODE END FMC_Init 2 */
}

static void MX_GPIO_Init(void)
{
  GPIO_InitTypeDef GPIO_InitStruct = {0};

  /* GPIO Ports Clock Enable */
  __HAL_RCC_GPIOE_CLK_ENABLE();
  __HAL_RCC_GPIOA_CLK_ENABLE();
  __HAL_RCC_GPIOB_CLK_ENABLE();
  __HAL_RCC_GPIOG_CLK_ENABLE();
  __HAL_RCC_GPIOJ_CLK_ENABLE();
  __HAL_RCC_GPIOD_CLK_ENABLE();
  __HAL_RCC_GPIOI_CLK_ENABLE();
  __HAL_RCC_GPIOK_CLK_ENABLE();
  __HAL_RCC_GPIOF_CLK_ENABLE();
  __HAL_RCC_GPIOH_CLK_ENABLE();
  __HAL_RCC_GPIOC_CLK_ENABLE();

  /*Configure GPIO pin Output Level */
  HAL_GPIO_WritePin(LCD_DISP_GPIO_Port, LCD_DISP_Pin, GPIO_PIN_RESET);

  /*Configure GPIO pin Output Level */
  HAL_GPIO_WritePin(GPIOB, LCD_RESET_Pin|ClrWDT_Pin, GPIO_PIN_RESET);

  /*Configure GPIO pin : LCD_DISP_Pin */
  GPIO_InitStruct.Pin = LCD_DISP_Pin;
  GPIO_InitStruct.Mode = GPIO_MODE_OUTPUT_PP;
  GPIO_InitStruct.Pull = GPIO_NOPULL;
  GPIO_InitStruct.Speed = GPIO_SPEED_FREQ_LOW;
  HAL_GPIO_Init(LCD_DISP_GPIO_Port, &GPIO_InitStruct);

  /*Configure GPIO pins : PH4 PH5 */
  GPIO_InitStruct.Pin = GPIO_PIN_4|GPIO_PIN_5;
  GPIO_InitStruct.Mode = GPIO_MODE_AF_OD;
  GPIO_InitStruct.Pull = GPIO_PULLUP;
  GPIO_InitStruct.Speed = GPIO_SPEED_FREQ_VERY_HIGH;
  GPIO_InitStruct.Alternate = GPIO_AF4_I2C2;
  HAL_GPIO_Init(GPIOH, &GPIO_InitStruct);

  /*Configure GPIO pin : LCD_INT_Pin */
  GPIO_InitStruct.Pin = LCD_INT_Pin;
  GPIO_InitStruct.Mode = GPIO_MODE_IT_FALLING;
  GPIO_InitStruct.Pull = GPIO_NOPULL;
  HAL_GPIO_Init(LCD_INT_GPIO_Port, &GPIO_InitStruct);

  /*Configure GPIO pins : LCD_RESET_Pin ClrWDT_Pin */
  GPIO_InitStruct.Pin = LCD_RESET_Pin|ClrWDT_Pin;
  GPIO_InitStruct.Mode = GPIO_MODE_OUTPUT_PP;
  GPIO_InitStruct.Pull = GPIO_NOPULL;
  GPIO_InitStruct.Speed = GPIO_SPEED_FREQ_LOW;
  HAL_GPIO_Init(GPIOB, &GPIO_InitStruct);

  /* EXTI interrupt init*/
  HAL_NVIC_SetPriority(EXTI0_IRQn, 5, 0);
  HAL_NVIC_EnableIRQ(EXTI0_IRQn);

}

void StartDefaultTask(void const * argument)
{
  for(;;)
  {
    osDelay(1);
  }
}

void StartTask02(void const * argument)
{
  /* USER CODE BEGIN StartTask02 */
	MX_TouchGFX_Process();
  /* Infinite loop */
  for(;;)
  {
    osDelay(1);
  }
  /* USER CODE END StartTask02 */
}

void StartTask03(void const * argument)
{
  /* USER CODE BEGIN StartTask03 */
	  HAL_GPIO_WritePin(LCD_RESET_GPIO_Port, LCD_RESET_Pin, GPIO_PIN_RESET);
	  osDelay(200);
	  HAL_GPIO_WritePin(LCD_RESET_GPIO_Port, LCD_RESET_Pin, GPIO_PIN_SET);
	  GT911_TEST();
  /* Infinite loop */
  for(;;)
  {
    osDelay(1);
  }
  /* USER CODE END StartTask03 */
}

void HAL_TIM_PeriodElapsedCallback(TIM_HandleTypeDef *htim)
{
  if (htim->Instance == TIM6) {
    HAL_IncTick();
  }
}

void Error_Handler(void)
{
  __disable_irq();
  while (1)
  {
  }
}
